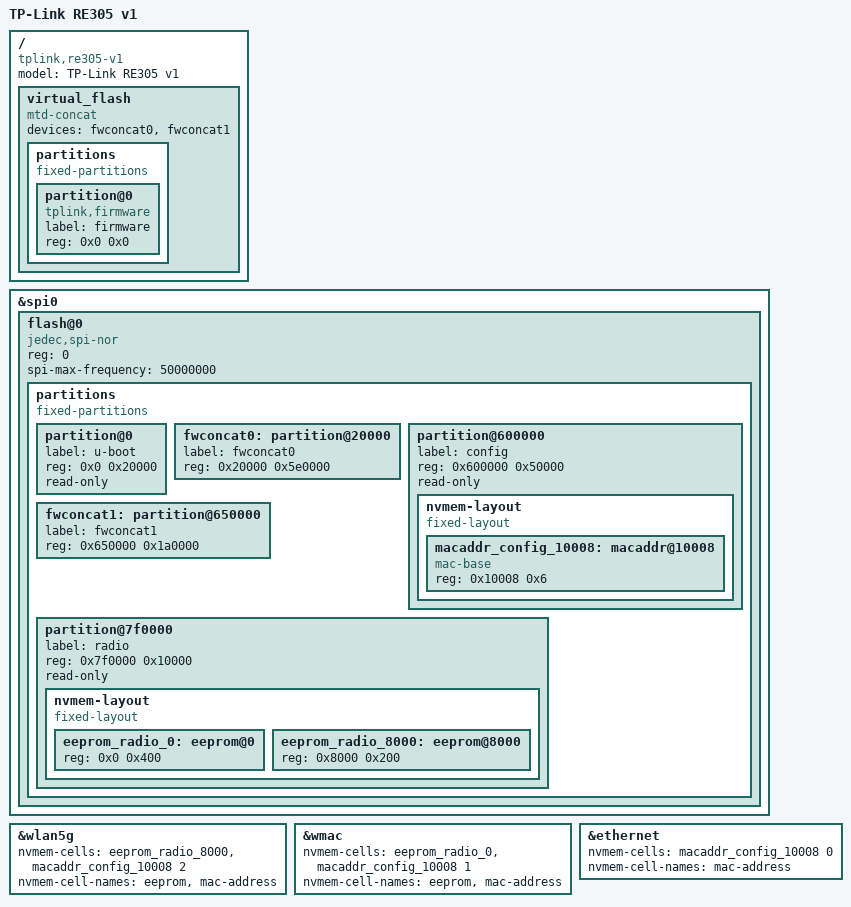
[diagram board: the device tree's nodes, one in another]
// SPDX-License-Identifier: GPL-2.0-or-later OR MIT

#include "mt7628an_tplink_re305.dtsi"

/ {
	compatible = "tplink,re305-v1", "mediatek,mt7628an-soc";
	model = "TP-Link RE305 v1";

	virtual_flash {
		compatible = "mtd-concat";
		devices = <&fwconcat0>, <&fwconcat1>;

		partitions {
			compatible = "fixed-partitions";
			#address-cells = <1>;
			#size-cells = <1>;

			partition@0 {
				compatible = "tplink,firmware";
				label = "firmware";
				reg = <0x0 0x0>;
			};
		};
	};
};

&spi0 {
	status = "okay";

	flash@0 {
		compatible = "jedec,spi-nor";
		reg = <0>;
		spi-max-frequency = <50000000>;

		partitions {
			compatible = "fixed-partitions";
			#address-cells = <1>;
			#size-cells = <1>;

			partition@0 {
				label = "u-boot";
				reg = <0x0 0x20000>;
				read-only;
			};

			fwconcat0: partition@20000 {
				label = "fwconcat0";
				reg = <0x20000 0x5e0000>;
			};

			partition@600000 {
				label = "config";
				reg = <0x600000 0x50000>;
				read-only;

				nvmem-layout {
					compatible = "fixed-layout";
					#address-cells = <1>;
					#size-cells = <1>;

					macaddr_config_10008: macaddr@10008 {
						compatible = "mac-base";
						reg = <0x10008 0x6>;
						#nvmem-cell-cells = <1>;
					};
				};
			};

			fwconcat1: partition@650000 {
				label = "fwconcat1";
				reg = <0x650000 0x1a0000>;
			};

			partition@7f0000 {
				label = "radio";
				reg = <0x7f0000 0x10000>;
				read-only;

				nvmem-layout {
					compatible = "fixed-layout";
					#address-cells = <1>;
					#size-cells = <1>;

					eeprom_radio_0: eeprom@0 {
						reg = <0x0 0x400>;
					};

					eeprom_radio_8000: eeprom@8000 {
						reg = <0x8000 0x200>;
					};
				};
			};
		};
	};
};

&wlan5g {
	nvmem-cells = <&eeprom_radio_8000>, <&macaddr_config_10008 2>;
	nvmem-cell-names = "eeprom", "mac-address";
};

&wmac {
	nvmem-cells = <&eeprom_radio_0>, <&macaddr_config_10008 1>;
	nvmem-cell-names = "eeprom", "mac-address";
};

&ethernet {
	nvmem-cells = <&macaddr_config_10008 0>;
	nvmem-cell-names = "mac-address";
};
